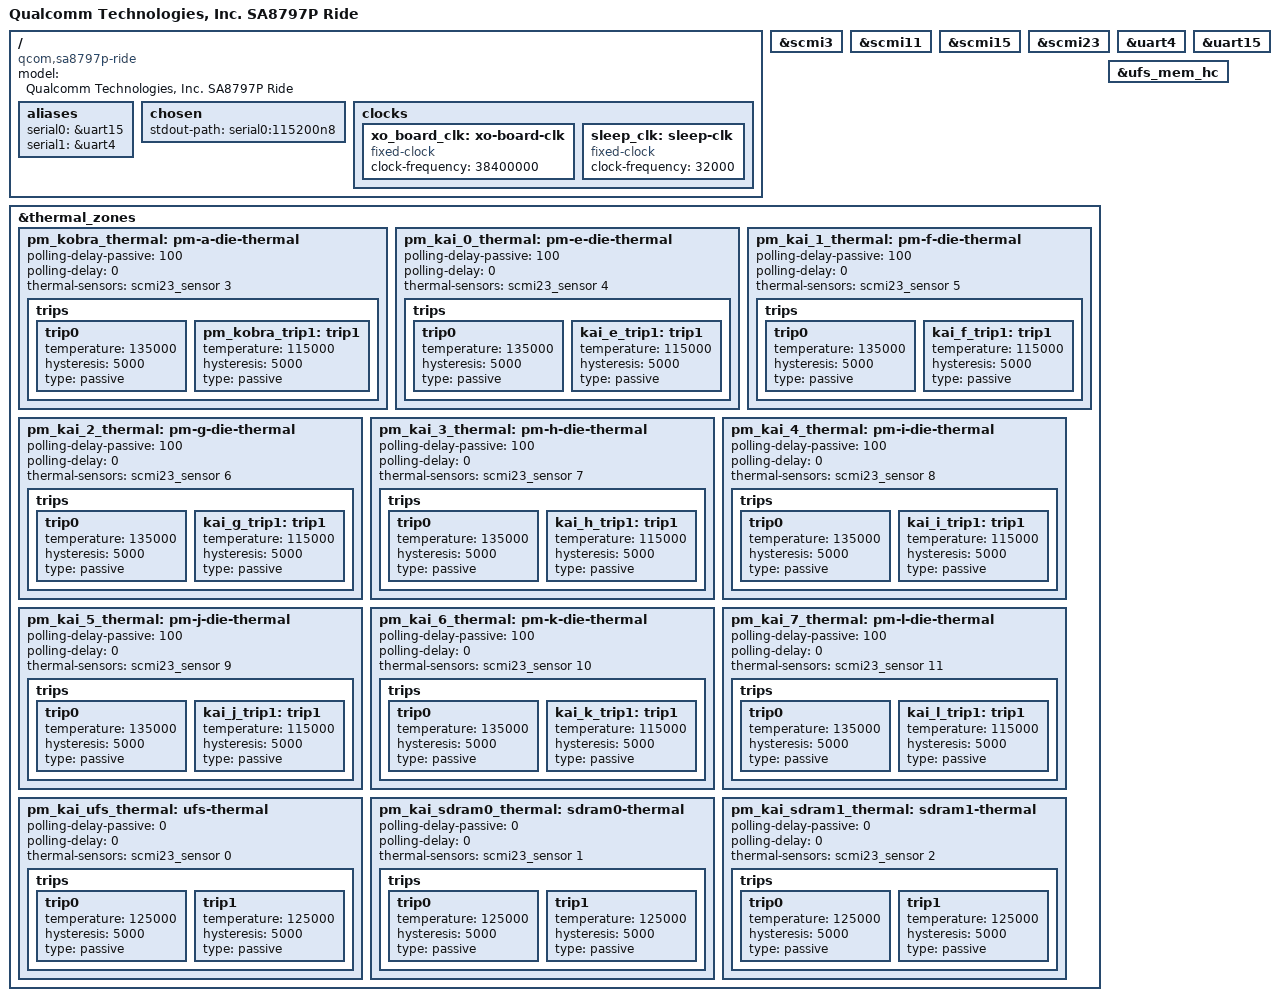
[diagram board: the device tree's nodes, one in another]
// SPDX-License-Identifier: BSD-3-Clause
/*
 * Copyright (c) Qualcomm Technologies, Inc. and/or its subsidiaries.
 */

/dts-v1/;

#include "nord-sa8797p.dtsi"

/ {
	model = "Qualcomm Technologies, Inc. SA8797P Ride";
	compatible = "qcom,sa8797p-ride", "qcom,sa8797p", "qcom,nord";

	aliases {
		serial0 = &uart15;
		serial1 = &uart4;
	};

	chosen {
		stdout-path = "serial0:115200n8";
	};

	clocks {
		xo_board_clk: xo-board-clk {
			compatible = "fixed-clock";
			clock-frequency = <38400000>;
			#clock-cells = <0>;
		};

		sleep_clk: sleep-clk {
			compatible = "fixed-clock";
			clock-frequency = <32000>;
			#clock-cells = <0>;
		};
	};
};

&scmi3 {
	status = "okay";
};

&scmi11 {
	status = "okay";
};

&scmi15 {
	status = "okay";
};

&scmi23 {
	status = "okay";
};

&thermal_zones {
	pm_kobra_thermal: pm-a-die-thermal {
		polling-delay-passive = <100>;
		polling-delay = <0>;
		thermal-sensors = <&scmi23_sensor 3>;

		trips {
			trip0 {
				temperature = <135000>;
				hysteresis = <5000>;
				type = "passive";
			};

			pm_kobra_trip1: trip1 {
				temperature = <115000>;
				hysteresis = <5000>;
				type = "passive";
			};
		};
	};

	pm_kai_0_thermal: pm-e-die-thermal {
		polling-delay-passive = <100>;
		polling-delay = <0>;
		thermal-sensors = <&scmi23_sensor 4>;

		trips {
			trip0 {
				temperature = <135000>;
				hysteresis = <5000>;
				type = "passive";
			};

			kai_e_trip1: trip1 {
				temperature = <115000>;
				hysteresis = <5000>;
				type = "passive";
			};
		};
	};

	pm_kai_1_thermal: pm-f-die-thermal {
		polling-delay-passive = <100>;
		polling-delay = <0>;
		thermal-sensors = <&scmi23_sensor 5>;

		trips {
			trip0 {
				temperature = <135000>;
				hysteresis = <5000>;
				type = "passive";
			};

			kai_f_trip1: trip1 {
				temperature = <115000>;
				hysteresis = <5000>;
				type = "passive";
			};
		};
	};

	pm_kai_2_thermal: pm-g-die-thermal {
		polling-delay-passive = <100>;
		polling-delay = <0>;
		thermal-sensors = <&scmi23_sensor 6>;

		trips {
			trip0 {
				temperature = <135000>;
				hysteresis = <5000>;
				type = "passive";
			};

			kai_g_trip1: trip1 {
				temperature = <115000>;
				hysteresis = <5000>;
				type = "passive";
			};
		};
	};

	pm_kai_3_thermal: pm-h-die-thermal {
		polling-delay-passive = <100>;
		polling-delay = <0>;
		thermal-sensors = <&scmi23_sensor 7>;

		trips {
			trip0 {
				temperature = <135000>;
				hysteresis = <5000>;
				type = "passive";
			};

			kai_h_trip1: trip1 {
				temperature = <115000>;
				hysteresis = <5000>;
				type = "passive";
			};
		};
	};

	pm_kai_4_thermal: pm-i-die-thermal {
		polling-delay-passive = <100>;
		polling-delay = <0>;
		thermal-sensors = <&scmi23_sensor 8>;

		trips {
			trip0 {
				temperature = <135000>;
				hysteresis = <5000>;
				type = "passive";
			};

			kai_i_trip1: trip1 {
				temperature = <115000>;
				hysteresis = <5000>;
				type = "passive";
			};
		};
	};

	pm_kai_5_thermal: pm-j-die-thermal {
		polling-delay-passive = <100>;
		polling-delay = <0>;
		thermal-sensors = <&scmi23_sensor 9>;

		trips {
			trip0 {
				temperature = <135000>;
				hysteresis = <5000>;
				type = "passive";
			};

			kai_j_trip1: trip1 {
				temperature = <115000>;
				hysteresis = <5000>;
				type = "passive";
			};
		};
	};

	pm_kai_6_thermal: pm-k-die-thermal {
		polling-delay-passive = <100>;
		polling-delay = <0>;
		thermal-sensors = <&scmi23_sensor 10>;

		trips {
			trip0 {
				temperature = <135000>;
				hysteresis = <5000>;
				type = "passive";
			};

			kai_k_trip1: trip1 {
				temperature = <115000>;
				hysteresis = <5000>;
				type = "passive";
			};
		};
	};

	pm_kai_7_thermal: pm-l-die-thermal {
		polling-delay-passive = <100>;
		polling-delay = <0>;
		thermal-sensors = <&scmi23_sensor 11>;

		trips {
			trip0 {
				temperature = <135000>;
				hysteresis = <5000>;
				type = "passive";
			};

			kai_l_trip1: trip1 {
				temperature = <115000>;
				hysteresis = <5000>;
				type = "passive";
			};
		};
	};

	pm_kai_ufs_thermal: ufs-thermal {
		polling-delay-passive = <0>;
		polling-delay = <0>;
		thermal-sensors = <&scmi23_sensor 0>;

		trips {
			trip0 {
				temperature = <125000>;
				hysteresis = <5000>;
				type = "passive";
			};

			trip1 {
				temperature = <125000>;
				hysteresis = <5000>;
				type = "passive";
			};
		};
	};

	pm_kai_sdram0_thermal: sdram0-thermal {
		polling-delay-passive = <0>;
		polling-delay = <0>;
		thermal-sensors = <&scmi23_sensor 1>;

		trips {
			trip0 {
				temperature = <125000>;
				hysteresis = <5000>;
				type = "passive";
			};

			trip1 {
				temperature = <125000>;
				hysteresis = <5000>;
				type = "passive";
			};
		};
	};

	pm_kai_sdram1_thermal: sdram1-thermal {
		polling-delay-passive = <0>;
		polling-delay = <0>;
		thermal-sensors = <&scmi23_sensor 2>;

		trips {
			trip0 {
				temperature = <125000>;
				hysteresis = <5000>;
				type = "passive";
			};

			trip1 {
				temperature = <125000>;
				hysteresis = <5000>;
				type = "passive";
			};
		};
	};
};

&uart4 {
	status = "okay";
};

&uart15 {
	status = "okay";
};

&ufs_mem_hc {
	status = "okay";
};
